# MKW38A4 register map
Vendor: NXP Semiconductors; Series: Kinetis_W; File version: 1.6
CPU: CM0PLUS r0p0, little endian, no MPU, no FPU, VTOR, 2 interrupt priority bits
Registers are 32-bit, read-write, no defined reset value unless marked. A register's access mark holds for its fields unless they carry their own. Offsets are from the block's base; [hi:lo] are bit positions; {n}, {i} and the like mark numbered series; 'fields as' and 'values as' point back to an identical list.

## PFLEXNVM — FAC
Base 0x4001F000
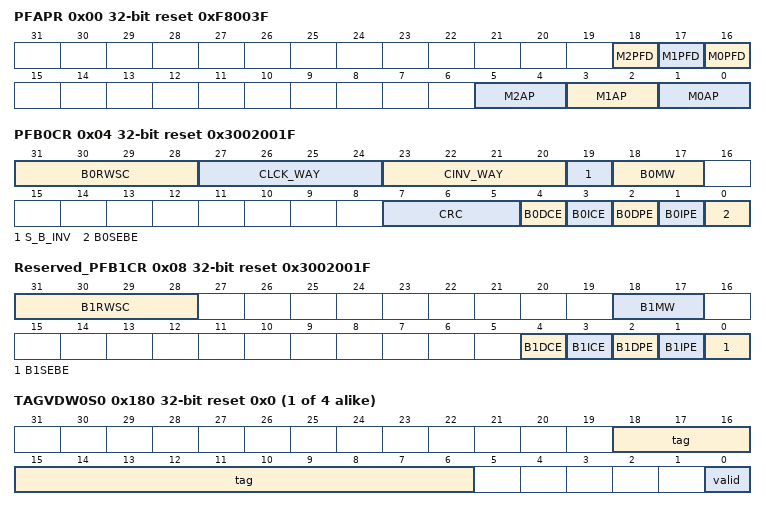
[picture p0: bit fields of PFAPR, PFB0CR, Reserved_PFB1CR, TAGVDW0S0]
0x00 PFAPR reset 0xF8003F — Flash Access Protection Register
  [18] M2PFD — Master 2 Prefetch Disable
    0=Prefetching for this master is enabled; 1=Prefetching for this master is disabled
  [17] M1PFD — Master 1 Prefetch Disable
    values as M2PFD
  [16] M0PFD — Master 0 Prefetch Disable
    values as M2PFD
  [5:4] M2AP — Master 2 Access Protection
    0=No access may be performed by this master; 1=Only read accesses may be performed by this master; 2=Only write accesses may be performed by this master; 3=Both read and write accesses may be performed by this master
  [3:2] M1AP — Master 1 Access Protection
    values as M2AP
  [1:0] M0AP — Master 0 Access Protection
    values as M2AP
0x04 PFB0CR reset 0x3002001F — Flash Bank 0 Control Register
  [31:28] B0RWSC ro — Bank 0 Read Wait State Control
  [27:24] CLCK_WAY — Cache Lock Way x
    0=Cache way is unlocked and may be displaced; 1=Cache way is locked and its contents are not displaced
  [23:20] CINV_WAY — Cache Invalidate Way x
    0=No cache way invalidation for the corresponding cache; 1=Invalidate cache way for the corresponding cache: clear the tag, data, and vld bits of ways selected
  [19] S_B_INV — Invalidate Prefetch Speculation Buffer
    0=Speculation buffer and single entry buffer are not affected; 1=Invalidate (clear) speculation buffer and single entry buffer
  [18:17] B0MW ro — Bank 0 Memory Width
    0=32 bits; 1=64 bits
  [7:5] CRC — Cache Replacement Control
    0=LRU replacement algorithm per set across all four ways; 2=Independent LRU with ways [0-1] for ifetches, [2-3] for data; 3=Independent LRU with ways [0-2] for ifetches, [3] for data
  [4] B0DCE — Bank 0 Data Cache Enable
    0=Do not cache data references; 1=Cache data references
  [3] B0ICE — Bank 0 Instruction Cache Enable
    0=Do not cache instruction fetches; 1=Cache instruction fetches
  [2] B0DPE — Bank 0 Data Prefetch Enable
    0=Do not prefetch in response to data references; 1=Enable prefetches in response to data references
  [1] B0IPE — Bank 0 Instruction Prefetch Enable
    0=Do not prefetch in response to instruction fetches; 1=Enable prefetches in response to instruction fetches
  [0] B0SEBE — Bank 0 Single Entry Buffer Enable
    0=Single entry buffer is disabled; 1=Single entry buffer is enabled
0x08 Reserved_PFB1CR reset 0x3002001F — Reserved Flash Bank 1 Control Register
  [31:28] B1RWSC ro — Bank 1 Read Wait State Control
  [18:17] B1MW ro — Bank 1 Memory Width
    0=32 bits; 1=64 bits
  [4] B1DCE — Bank 1 Data Cache Enable
    0=Do not cache data references; 1=Cache data references
  [3] B1ICE — Bank 1 Instruction Cache Enable
    values as PFB0CR.B0ICE
  [2] B1DPE — Bank 1 Data Prefetch Enable
    values as PFB0CR.B0DPE
  [1] B1IPE — Bank 1 Instruction Prefetch Enable
    values as PFB0CR.B0IPE
  [0] B1SEBE — Bank 1 Single Entry Buffer Enable
    values as PFB0CR.B0SEBE
{0x180+0x10*i} TAGVDW{i}S0 reset 0x0 (i=0..3) — Cache Tag Storage
  [18:6] tag — 13-bit tag for cache entry
  [0] valid — 1-bit valid for cache entry
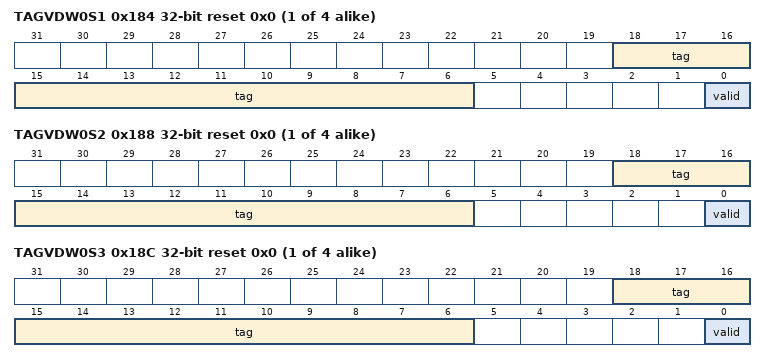
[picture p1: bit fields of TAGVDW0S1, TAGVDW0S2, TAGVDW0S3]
{0x184+0x10*i} TAGVDW{i}S1 reset 0x0 (i=0..3) — Cache Tag Storage
  fields as TAGVDW0S0
{0x188+0x10*i} TAGVDW{i}S2 reset 0x0 (i=0..3) — Cache Tag Storage
  fields as TAGVDW0S0
{0x18C+0x10*i} TAGVDW{i}S3 reset 0x0 (i=0..3) — Cache Tag Storage
  fields as TAGVDW0S0
{0x300+0x20*i} DATAW{i}S0U reset 0x0 (i=0..3) — Cache Data Storage (upper word)
  [31:0] data — Bits [63:32] of data entry
{0x304+0x20*i} DATAW{i}S0L reset 0x0 (i=0..3) — Cache Data Storage (lower word)
  [31:0] data — Bits [31:0] of data entry
{0x308+0x20*i} DATAW{i}S1U reset 0x0 (i=0..3) — Cache Data Storage (upper word)
  [31:0] data — Bits [63:32] of data entry
{0x30C+0x20*i} DATAW{i}S1L reset 0x0 (i=0..3) — Cache Data Storage (lower word)
  [31:0] data — Bits [31:0] of data entry
{0x310+0x20*i} DATAW{i}S2U reset 0x0 (i=0..3) — Cache Data Storage (upper word)
  [31:0] data — Bits [63:32] of data entry
{0x314+0x20*i} DATAW{i}S2L reset 0x0 (i=0..3) — Cache Data Storage (lower word)
  [31:0] data — Bits [31:0] of data entry
{0x318+0x20*i} DATAW{i}S3U reset 0x0 (i=0..3) — Cache Data Storage (upper word)
  [31:0] data — Bits [63:32] of data entry
{0x31C+0x20*i} DATAW{i}S3L reset 0x0 (i=0..3) — Cache Data Storage (lower word)
  [31:0] data — Bits [31:0] of data entry
